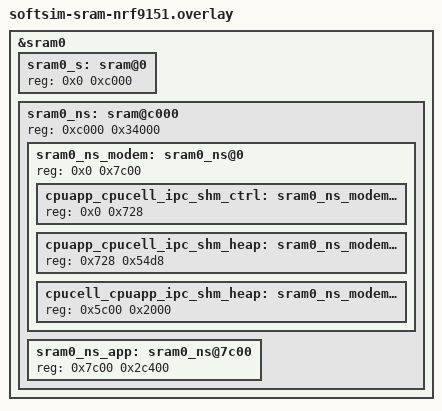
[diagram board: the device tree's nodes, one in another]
/*
 * Copyright (c) 2026 Nordic Semiconductor ASA
 *
 * SPDX-License-Identifier: LicenseRef-Nordic-5-Clause
 */

/*
 * Application SRAM layout for nRF9151 DK with SoftSIM (application only, B0 and MCUboot
 * keep their default SRAM layout):
 *
 * 0x2000_0000  Secure RAM                   (  48 kB)
 * 0x2000_c000  Non-secure RAM area          ( 208 kB)
 *   0x2000_c000  Modem shared area          (  31 kB)
 *     0x2000_c000  control                  (1832 B)
 *     0x2000_c728  app -> cell              (21720 B)
 *     0x2001_1c00  cell -> app              (   8 kB)
 *   0x2001_3c00  Application RAM            ( 177 kB)
 */

/delete-node/ &sram0_s;
/delete-node/ &sram0_ns;

&sram0 {

	sram0_s: sram@0 {
		reg = <0x0 0xc000>;
	};

	sram0_ns: sram@c000 {
		reg = <0xc000 0x34000>;
		#address-cells = <1>;
		#size-cells = <1>;
		ranges = <0x0 0xc000 0x34000>;

		/* Must be in first 128 kB of RAM. */
		sram0_ns_modem: sram0_ns@0 {
			/* Modem (shared) memory */
			reg = <0x0 0x7c00>;
			#address-cells = <1>;
			#size-cells = <1>;
			ranges = <0x0 0x0 0x7c00>;

			cpuapp_cpucell_ipc_shm_ctrl: sram0_ns_modem@0 {
				/* Modem IPC control */
				reg = <0x0 0x728>;
			};

			cpuapp_cpucell_ipc_shm_heap: sram0_ns_modem@728 {
				/* Modem IPC transmit */
				reg = <0x728 0x54d8>;
			};

			cpucell_cpuapp_ipc_shm_heap: sram0_ns_modem@5c00 {
				/* Modem IPC receive */
				reg = <0x5c00 0x2000>;
			};
		};

		sram0_ns_app: sram0_ns@7c00 {
			/* Non-Secure application memory */
			reg = <0x7c00 0x2c400>;
		};
	};
};
